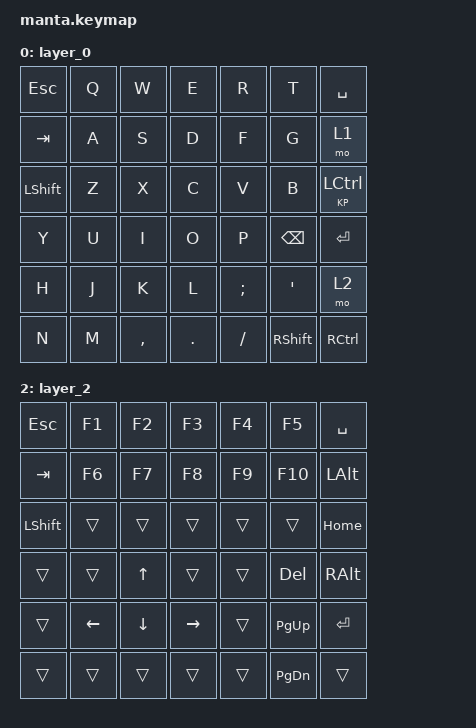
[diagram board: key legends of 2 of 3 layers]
#include <behaviors.dtsi>
#include <dt-bindings/zmk/keys.h>

/ {
    keymap {
        compatible = "zmk,keymap";

        layer_0 {
            bindings = <
                /* Left half */
                &kp ESC    &kp Q    &kp W    &kp E    &kp R    &kp T   &kp SPACE
                &kp TAB    &kp A    &kp S    &kp D    &kp F    &kp G   &mo 1
                &kp LSHFT  &kp Z    &kp X    &kp C    &kp V    &kp B   &KP LCTRL

                /* Right half */
                &kp Y      &kp U    &kp I    &kp O    &kp P     &kp BSPC   &kp ENTER
                &kp H      &kp J    &kp K    &kp L    &kp SEMI  &kp SQT    &mo 2
                &kp N      &kp M    &kp COMMA &kp DOT &kp FSLH  &kp RSHFT  &kp RCTRL
            >;
        };

        layer_1 {
            bindings = <
                /* Left half */
                &kp GRAVE      &kp N1          &kp N2        &kp N3        &kp N4         &kp N5         &kp SPACE
                &kp TILDE      &kp LS(EXCL)    &kp LS(AT)    &kp LS(POUND) &kp LS(DLLR)   &kp LS(PRCNT)  &kp LALT
                &kp PRINTSCREEN &kp LS(UNDER)  &kp DOT       &kp EQUAL     &kp LS(PLUS)   &kp LGUI       &kp LCTRL

                /* Right half */
                &kp N6         &kp N7          &kp N8        &kp N9        &kp N0         &kp BSPC  &kp ENTER 
                &kp LS(CARET)  &kp LS(AMPS)    &kp LS(STAR)  &kp LS(LPAR)  &kp LS(RPAR)   &kp BSLH  &kp RALT
                &kp MINUS      &kp LBKT        &kp RBKT      &kp LS(LBRC)  &kp LS(RBRC)   &kp RSHFT &kp END
                &kp RALT       &kp END         &kp RET
            >;
        };

        layer_2 {
            bindings = <
                /* Left half */
                &kp ESC    &kp F1    &kp F2    &kp F3    &kp F4    &kp F5  &kp SPACE
                &kp TAB    &kp F6    &kp F7    &kp F8    &kp F9    &kp F10 &kp LALT
                &kp LSHFT  &trans    &trans    &trans    &trans    &trans  &kp HOME

                /* Right half */
                &trans     &trans    &kp UP    &trans    &trans    &kp DEL   &kp RALT
                &trans     &kp LEFT  &kp DOWN  &kp RIGHT &trans    &kp PG_UP &kp RET
                &trans     &trans    &trans    &trans    &trans    &kp PG_DN &trans
            >;
        };
    };
};
